# MCU_CTRL_MMR0_CFG0 register map
Vendor: Texas Instruments
Registers are 32-bit, read-write, reset 0x0 unless marked. A register's access mark holds for its fields unless they carry their own. Offsets are as the file gives them; [hi:lo] are bit positions; {n}, {i} and the like mark numbered series.

## MCU_CTRL_MMR0_CFG0 (part 3 of 3)
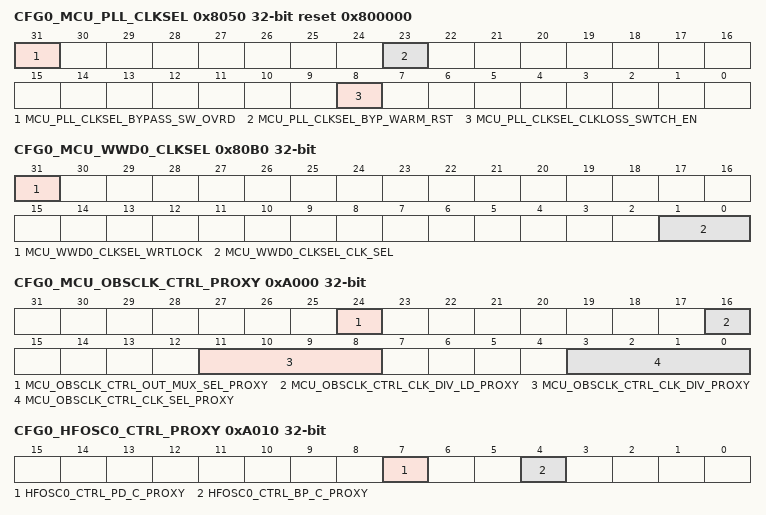
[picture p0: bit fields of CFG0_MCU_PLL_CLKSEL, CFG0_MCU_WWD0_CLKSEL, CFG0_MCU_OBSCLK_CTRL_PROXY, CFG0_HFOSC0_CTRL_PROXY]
0x8050 CFG0_MCU_PLL_CLKSEL reset 0x800000
  [31] MCU_PLL_CLKSEL_BYPASS_SW_OVRD — PLL Bypass warm reset software override When set, activates software control of exit from bypass mode on a mcu_reset_z for MCU_PLL0. This bit must not be set until after the corresponding byp_warm_rst bit has been cleared or the PLL will immediately enter bypass mode. Field values (others are reserved): 1'b0 - DEACTIVATE 1'b1 - ACTIVATE
  [23] MCU_PLL_CLKSEL_BYP_WARM_RST — PLL bypass mode after warm reset. This bit is only valid when bypass_sw_ovrd is set to 1'b1 to activate bypass software override. This bit is set (1'b1) when a MCU warm reset occurs and will keep MCU_PLL0 in bypass mode after reset exit until cleared by software. Field values (others are reserved): 1'b0 - EXIT_BYPASS 1'b1 - MAINTAIN_BYPASS
  [8] MCU_PLL_CLKSEL_CLKLOSS_SWTCH_EN — When set, activates automatic switching of MCU_PLL0 clock source to CLK_12M_RC if HFOSC0 clock loss is detected Field values (others are reserved): 1'b0 - DEACTIVATE 1'b1 - ACTIVATE
0x8058 CFG0_DEVICE_CLKOUT_32K_CTRL
  [1:0] DEVICE_CLKOUT_32K_CTRL_CLK_32K_RC_SEL — Selects the source of the device level 32KHz Clock Field values (others are reserved): 2'b00 - CLK_32K_RC 2'b01 - HFOSC0_CLKOUT_32K undefined - undefined 2'b11 - LFOSC0_CLKOUT
{0x8060+4i} CFG0_MCU_TIMER{i}_CLKSEL (i=0..3)
  [2:0] MCU_TIMER{i}_CLKSEL_CLK_SEL — Timer functional clock input select mux control (Reserved values default to HFOSC0_CLK) Field values (others are reserved): 3'b000 - HFOSC0_CLKOUT 3'b001 - MCU_SYSCLK0 / 2 3'b010 - CLK_12M_RC 3'b011 - MCU_PLL0_HSDIV5_CLKOUT 3'b100 - MCU_EXT_REFCLK0 3'b101 - DEVICE_CLKOUT_32K 3'b110 - CPSW0_CPTS_GENF0 3'b111 - CLK_32K_RC
0x8070 CFG0_MCU_GPIO_CLKSEL
  [1:0] MCU_GPIO_CLKSEL_CLK_SEL — MCU_GPIO clock selection. Must be set to MCU_SYSCLK0/4 whenever MCU_GPIO VBUS interface is activated. Other clock source may be selected as a clk_sel up clock for DeepSleep modes after MCU_GPIO is gated off through LPSC. Field values (others are reserved): 2'b00 - MCU_SYSCLK0_DIV4 2'b01 - LFSOSC_CLKOUT 2'b10 - CLK_32K 2'b11 - CLK_12M_RC
0x8080 CFG0_MCU_MCAN0_CLKSEL
  [1:0] MCU_MCAN0_CLKSEL_CLK_SEL — Selects the clock source for MCAN0 Field values (others are reserved): 2'b00 - MCU_PLL0_HSDIV4_CLKOUT 2'b01 - MCU_EXT_REFCLK0 2'b10 - HFOSC0_CLKOUT 2'b11 - HFOSC0_CLKOUT
0x8084 CFG0_MCU_MCAN1_CLKSEL
  [1:0] MCU_MCAN1_CLKSEL_CLK_SEL — Selects the clock source for MCAN1 Field values (others are reserved): 2'b00 - MCU_PLL0_HSDIV4_CLKOUT 2'b01 - MCU_EXT_REFCLK0 2'b10 - HFOSC0_CLKOUT 2'b11 - HFOSC0_CLKOUT
0x80A0 CFG0_MCU_SPI0_CLKSEL
  [16] MCU_SPI0_CLKSEL_MSTR_LB_CLKSEL — Controller mode receive capture clock loopback selection Field values (others are reserved): 1'b0 - INTERNAL_LOOPBACK 1'b1 - EXTERNAL_LOOPBACK
0x80A4 CFG0_MCU_SPI1_CLKSEL
  [16] MCU_SPI1_CLKSEL_MSTR_LB_CLKSEL — Controller mode receive capture clock loopback selection Field values (others are reserved): 1'b0 - INTERNAL_LOOPBACK 1'b1 - EXTERNAL_LOOPBACK
0x80B0 CFG0_MCU_WWD0_CLKSEL
  [31] MCU_WWD0_CLKSEL_WRTLOCK — When set, locks WWD0_CLKSEL from further writes until the next module reset. Field values (others are reserved): 1'b0 - UNLOCKED 1'b1 - LOCKED
  [1:0] MCU_WWD0_CLKSEL_CLK_SEL — Windowed watchdog timer functional clock input select mux control Field values (others are reserved): 2'b00 - HFOSC0_CLKOUT 2'b01 - DEVICE_CLKOUT_32K 2'b10 - CLK_12M_RC 2'b11 - CLK_32K_RC
0x9100 CFG0_CLAIMREG_P2_R0_READONLY ro
  [31:0] CLAIMREG_P2_R0_READONLY — Claim bits for Partition 2
0x9104 CFG0_CLAIMREG_P2_R1_READONLY ro
  [31:0] CLAIMREG_P2_R1_READONLY — Claim bits for Partition 2
0xA000 CFG0_MCU_OBSCLK_CTRL_PROXY
  [24] MCU_OBSCLK_CTRL_OUT_MUX_SEL_PROXY — MCU_OBSCLK pin output mux selection. Note, HFOSC0_CLK is a direct output from the HFOSC0, distinct from HFOSC0_CLKOUT. Note, when HFOSC0_CLK is selected (1'b1) the MCU_OBSCLK_CTRL_clk_sel field must be programmed to 4'b0001. Field values (others are reserved): 1'b0 - CLK_DIV_OUT 1'b1 - HFOSC0_CLK (clk_sel must be OFF)
  [16] MCU_OBSCLK_CTRL_CLK_DIV_LD_PROXY — Load the output divider value Writing 1 to this bit will generate a load pulse to load the OBSCLK divider value. This bit can be cleared but must not be set in the same write cycle in which the clk_div value is changed. Field values (others are reserved): 1'b0 - READY 1'b1 - LOAD
  [11:8] MCU_OBSCLK_CTRL_CLK_DIV_PROXY — MCU_OBSCLK pin clock selection output divider Output clock is divided by clk_div+1
  [3:0] MCU_OBSCLK_CTRL_CLK_SEL_PROXY — MCU_OBSCLK pin clock selection Field values (others are reserved): 4'b0000 - CLK_12M_RC 4'b0001 - OFF 4'b0010 - MCU_PLL0_HSDIV0_CLKOUT 4'b0011 - MCU_PLL0_HSDIV4_CLKOUT 4'b0100 - MCU_PLLCTRL_OBSCLK 4'b0101 - CLK_32K_RC 4'b0110 - HFOSC0_CLKOUT 4'b0111 - HFOSC0_CLKOUT_32K 4'b1000 - MCU_SYSCLK0 4'b1001 - DEVICE_CLKOUT_32K
0xA010 CFG0_HFOSC0_CTRL_PROXY
  [7] HFOSC0_CTRL_PD_C_PROXY — Oscillator powerdown control. Field values (others are reserved): 1'b0 - ACTIVE 1'b1 - POWERDOWN
  [4] HFOSC0_CTRL_BP_C_PROXY — Must Write '0'
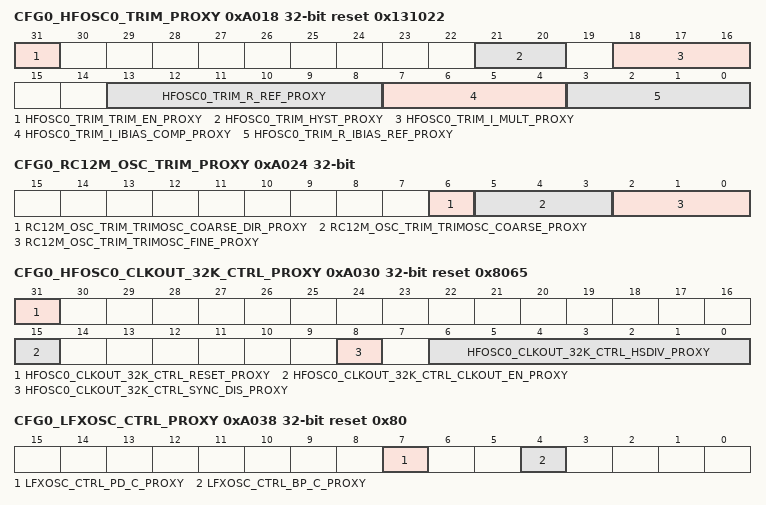
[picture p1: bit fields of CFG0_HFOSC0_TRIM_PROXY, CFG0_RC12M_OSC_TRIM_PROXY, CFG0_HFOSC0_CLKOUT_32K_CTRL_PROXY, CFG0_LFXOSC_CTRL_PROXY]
0xA018 CFG0_HFOSC0_TRIM_PROXY reset 0x131022
  [31] HFOSC0_TRIM_TRIM_EN_PROXY — Apply MMR values to OSC trim inputs instead of tie-offs Field values (others are reserved): 1'b0 - FIXED_TRIM 1'b1 - MMR_TRIM
  [21:20] HFOSC0_TRIM_HYST_PROXY — Sets comparator hysterisis Field values (others are reserved): 2'b00 - NO_HYS 2'b01 - TYPE1_HYS 2'b10 - TYPE2_HYS 2'b11 - BOTH_TYPES_HYS
  [18:16] HFOSC0_TRIM_I_MULT_PROXY — AGC AMP current multiplication gain Field values (others are reserved): 3'b000 - GAIN_0P250X 3'b001 - GAIN_0P375X 3'b010 - GAIN_0P500X 3'b011 - GAIN_0P625X 3'b100 - GAIN_0P750X 3'b101 - GAIN_0P875X 3'b110 - GAIN_1X 3'b111 - GAIN_1P250X
  [13:8] HFOSC0_TRIM_R_REF_PROXY — Sets the AMP AGC bias current Field values (others are reserved): 6'b000000 - R_REF_4X 6'b001000 - R_REF_6X 6'b010000 - R_REF_8X 6'b011000 - R_REF_10X 6'b100000 - R_REF_12X 6'b101000 - R_REF_14X 6'b110000 - R_REF_16X 6'b111000 - R_REF_18X
  [7:4] HFOSC0_TRIM_I_IBIAS_COMP_PROXY — Sets the COMP bias current Field values (others are reserved): 4'b0000 - I_BIAS_COMP_2P00X 4'b0001 - I_BIAS_COMP_2P25X 4'b0010 - I_BIAS_COMP_2P50X 4'b0011 - I_BIAS_COMP_2P75X 4'b0100 - I_BIAS_COMP__2P50X 4'b0101 - I_BIAS_COMP__2P75X 4'b0110 - I_BIAS_COMP_3P00X 4'b0111 - I_BIAS_COMP_3P25X 4'b1000 - I_BIAS_COMP__3P00X 4'b1001 - I_BIAS_COMP__3P25X 4'b1010 - I_BIAS_COMP_3P50X 4'b1011 - I_BIAS_COMP_3P75X 4'b1100 - I_BIAS_COMP_3P50X 4'b1101 - I_BIAS_COMP_3P75X 4'b1110 - I_BIAS_COMP_4P00X 4'b1111 - I_BIAS_COMP_4P25X
  [3:0] HFOSC0_TRIM_R_IBIAS_REF_PROXY — Sets the base IBIAS reference Field values (others are reserved): 4'b0000 - IBIAS_REF_1X 4'b0001 - IBIAS_REF_5X 4'b0010 - IBIAS_REF_3X (Default) 4'b0011 - IBIAS_REF_7X
0xA020 CFG0_HFOSC0_STAT_PROXY ro
  [0] HFOSC0_STAT_DS_ON_WFI_STAT_PROXY — Reflects the status of Device Manager Request to Disable HFOSC0 when it enters the WFI state (DeepSleep Entry) Field values (others are reserved): 1'b0 - NO_DEEPSLEEP_REQUEST 1'b1 - DEEPSLEEP_REQUEST
0xA024 CFG0_RC12M_OSC_TRIM_PROXY
  [6] RC12M_OSC_TRIM_TRIMOSC_COARSE_DIR_PROXY — Coarse adjustment direction. Field values (others are reserved): 1'b0 - TRIM_FREQ_LOWER 1'b1 - TRIM_FREQ_HIGHER
  [5:3] RC12M_OSC_TRIM_TRIMOSC_COARSE_PROXY — Coarse adjustment. Frequency is decreased or increased by 1.25 MHz per value based on the trimosc_coarse_dir value. Field values (others are reserved): 3'b000 - TRIM_0_MHZ 3'b001 - TRIM_1P25_MHZ 3'b010 - TRIM_2P50_MHZ 3'b011 - TRIM_3P75_MHZ 3'b100 - TRIM_4P00_MHZ 3'b101 - TRIM_5P25_MHZ 3'b110 - TRIM_6P50_MHZ 3'b111 - TRIM_7P75_MHZ
  [2:0] RC12M_OSC_TRIM_TRIMOSC_FINE_PROXY — Fine adjustment. Decreases the frequency by 250 KHz per value. Field values (others are reserved): 3'b000 - TRIM_0_KHZ 3'b001 - TRIM_250_KHZ 3'b010 - TRIM_500_KHZ 3'b011 - TRIM_750_KHZ 3'b100 - TRIM_1000_KHZ 3'b101 - TRIM_1250_KHZ 3'b110 - TRIM_1500_KHZ 3'b111 - TRIM_1750_KHZ
0xA030 CFG0_HFOSC0_CLKOUT_32K_CTRL_PROXY reset 0x8065
  [31] HFOSC0_CLKOUT_32K_CTRL_RESET_PROXY — Asynchronous Divider Reset. Field values (others are reserved): 1'b0 - ACTIVE 1'b1 - RESET
  [15] HFOSC0_CLKOUT_32K_CTRL_CLKOUT_EN_PROXY — HFOSC0_CLKOUT_32K output active Field values (others are reserved): 1'b0 - INACTIVE 1'b1 - ACTIVE
  [8] HFOSC0_CLKOUT_32K_CTRL_SYNC_DIS_PROXY — HFOSC0_CLKOUT_32K Synchronize Deactivate This bit must be written 0. Field values (others are reserved): 1'b0 - NORMAL
  [6:0] HFOSC0_CLKOUT_32K_CTRL_HSDIV_PROXY — HFOSC0_CLKOUT_32K divider: HFOSC0_CLKKOUT_32K Frequency = HFOSC0 Frequency / [8 * (hsdiv + 1)] Ex. HFOSC0 Frequency = 26MHz. hsdiv = 101 (Default) HFOSC0_CLKOUT_32K = 26MHz / (8 * (101+1)) = 26MHz / 816 = 31.9 KHz
0xA038 CFG0_LFXOSC_CTRL_PROXY reset 0x80
  [7] LFXOSC_CTRL_PD_C_PROXY — Oscillator powerdown control. When set, oscillator is deactivated. Oscillator output is tristated if bp_c=0 Field values (others are reserved): 1'b0 - ACTIVE 1'b1 - POWERDOWN
  [4] LFXOSC_CTRL_BP_C_PROXY — Oscillator bypass control. When set, oscillator is in bypass mode Field values (others are reserved): 1'b0 - ACTIVE 1'b1 - BYPASS
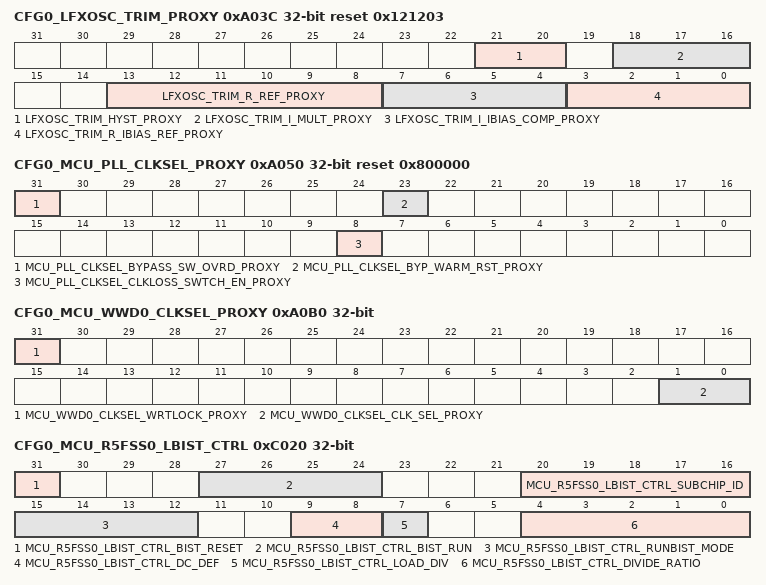
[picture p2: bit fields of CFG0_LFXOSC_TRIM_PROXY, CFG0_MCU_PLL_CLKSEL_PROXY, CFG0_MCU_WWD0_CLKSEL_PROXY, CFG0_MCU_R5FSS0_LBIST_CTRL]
0xA03C CFG0_LFXOSC_TRIM_PROXY reset 0x121203
  [21:20] LFXOSC_TRIM_HYST_PROXY — Sets comparator hysterisis Field values (others are reserved): 2'b00 - NO_HYS 2'b01 - TYPE1_HYS 2'b10 - TYPE2_HYS 2'b11 - BOTH_TYPES_HYS
  [18:16] LFXOSC_TRIM_I_MULT_PROXY — AGC AMP current multiplication gain Field values (others are reserved): 3'b000 - AMP_AGC_IBIAS_3X 3'b001 - AMP_AGC_IBIAS_4X 3'b010 - AMP_AGC_IBIAS_5X 3'b011 - AMP_AGC_IBIAS_6X 3'b100 - AMP_AGC_IBIAS_7X 3'b101 - AMP_AGC_IBIAS_8X 3'b110 - AMP_AGC_IBIAS_9X 3'b111 - AMP_AGC_IBIAS_10X
  [13:8] LFXOSC_TRIM_R_REF_PROXY — Sets the AMP AGC bias current Field values (others are reserved): 6'b000000 - OHMS_0K 6'b000001 - OHMS_24K 6'b000010 - OHMS_48K 6'b000011 - OHMS_73K 6'b000100 - OHMS_97K 6'b000101 - OHMS_121K 6'b000110 - OHMS_145K 6'b000111 - OHMS_169K 6'b001000 - OHMS_193K 6'b001001 - OHMS_218K 6'b001010 - OHMS_242K 6'b001011 - OHMS_266K 6'b001100 - OHMS_290K 6'b001101 - OHMS_314K 6'b001110 - OHMS_338K 6'b001111 - OHMS_363K 6'b010000 - OHMS_387K 6'b010001 - OHMS_411K 6'b010010 - OHMS_435K (Default) 6'b010011 - OHMS_459K 6'b010100 - OHMS_483K 6'b010101 - OHMS_508K 6'b010110 - OHMS_532K 6'b010111 - OHMS_556K 6'b011000 - OHMS_580K 6'b011001 - OHMS_604K 6'b011010 - OHMS_628K 6'b011011 - OHMS_653K 6'b011100 - OHMS_677K 6'b011101 - OHMS_701K 6'b011110 - OHMS_725K 6'b011111 - OHMS_749K 6'b100000 - OHMS_773K 6'b100001 - OHMS_798K 6'b100010 - OHMS_822K 6'b100011 - OHMS_846K 6'b100100 - OHMS_870K 6'b100101 - OHMS_894K 6'b100110 - OHMS_918K 6'b100111 - OHMS_943K 6'b101000 - OHMS_967K 6'b101001 - OHMS_991K 6'b101010 - OHMS_1015K 6'b101011 - OHMS_1039K 6'b101100 - OHMS_1063K 6'b101101 - OHMS_1088K 6'b101110 - OHMS_1112K 6'b101111 - OHMS_1136K 6'b110000 - OHMS_1160K 6'b110001 - OHMS_1184K 6'b110010 - OHMS_1208K 6'b110011 - OHMS_1233K 6'b110100 - OHMS_1257K 6'b110101 - OHMS_1281K 6'b110110 - OHMS_1305K 6'b110111 - OHMS_1329K 6'b111000 - OHMS_1353K 6'b111001 - OHMS_1378K 6'b111010 - OHMS_1402K 6'b111011 - OHMS_1426K 6'b111100 - OHMS_1450K 6'b111101 - OHMS_1474K 6'b111110 - OHMS_1498K 6'b111111 - OHMS_1523K
  [7:4] LFXOSC_TRIM_I_IBIAS_COMP_PROXY — Sets the COMP bias current Field values (others are reserved): 4'b0000 - BASE_IBIAS_REF_X2 4'b0001 - BASE_IBIAS_REF_X3 4'b0010 - BASE_IBIAS_REF_X4 4'b0011 - BASE_IBIAS_REF_X5 4'b0100 - BASE_IBIAS_REF_X6 4'b0101 - BASE_IBIAS_REF_X7 4'b0110 - BASE_IBIAS_REF_X8 4'b0111 - BASE_IBIAS_REF_X9 4'b1000 - BASE_IBIAS_REF_X10 4'b1001 - BASE_IBIAS_REF_X11 4'b1010 - BASE_IBIAS_REF_X12 4'b1011 - BASE_IBIAS_REF_X13 4'b1100 - BASE_IBIAS_REF_X14 4'b1101 - BASE_IBIAS_REF_X15 4'b1110 - BASE_IBIAS_REF_X16 4'b1111 - BASE_IBIAS_REF_X17
  [3:0] LFXOSC_TRIM_R_IBIAS_REF_PROXY — Sets the base IBIAS reference Field values (others are reserved): 4'b0000 - OHMS_512K 4'b0001 - OHMS_576K 4'b0010 - OHMS_640K 4'b0011 - OHMS_704K (Default) 4'b0100 - OHMS_768K 4'b0101 - OHMS_832K 4'b0110 - OHMS_896K 4'b0111 - OHMS_960K 4'b1000 - OHMS_1024K 4'b1001 - OHMS_1088K 4'b1010 - OHMS_1152K 4'b1011 - OHMS_1216K 4'b1100 - OHMS_1280K 4'b1101 - OHMS_1344K 4'b1110 - OHMS_1408K 4'b1111 - OHMS_1472K
0xA050 CFG0_MCU_PLL_CLKSEL_PROXY reset 0x800000
  [31] MCU_PLL_CLKSEL_BYPASS_SW_OVRD_PROXY — PLL Bypass warm reset software override When set, activates software control of exit from bypass mode on a mcu_reset_z for MCU_PLL0. This bit must not be set until after the corresponding byp_warm_rst bit has been cleared or the PLL will immediately enter bypass mode. Field values (others are reserved): 1'b0 - DEACTIVATE 1'b1 - ACTIVATE
  [23] MCU_PLL_CLKSEL_BYP_WARM_RST_PROXY — PLL bypass mode after warm reset. This bit is only valid when bypass_sw_ovrd is set to 1'b1 to activate bypass software override. This bit is set (1'b1) when a MCU warm reset occurs and will keep MCU_PLL0 in bypass mode after reset exit until cleared by software. Field values (others are reserved): 1'b0 - EXIT_BYPASS 1'b1 - MAINTAIN_BYPASS
  [8] MCU_PLL_CLKSEL_CLKLOSS_SWTCH_EN_PROXY — When set, activates automatic switching of MCU_PLL0 clock source to CLK_12M_RC if HFOSC0 clock loss is detected Field values (others are reserved): 1'b0 - DEACTIVATE 1'b1 - ACTIVATE
0xA058 CFG0_DEVICE_CLKOUT_32K_CTRL_PROXY
  [1:0] DEVICE_CLKOUT_32K_CTRL_CLK_32K_RC_SEL_PROXY — Selects the source of the device level 32KHz Clock Field values (others are reserved): 2'b00 - CLK_32K_RC 2'b01 - HFOSC0_CLKOUT_32K undefined - undefined 2'b11 - LFOSC0_CLKOUT
{0xA060+4i} CFG0_MCU_TIMER{i}_CLKSEL_PROXY (i=0..3)
  [2:0] MCU_TIMER{i}_CLKSEL_CLK_SEL_PROXY — Timer functional clock input select mux control (Reserved values default to HFOSC0_CLK) Field values (others are reserved): 3'b000 - HFOSC0_CLKOUT 3'b001 - MCU_SYSCLK0 / 2 3'b010 - CLK_12M_RC 3'b011 - MCU_PLL0_HSDIV5_CLKOUT 3'b100 - MCU_EXT_REFCLK0 3'b101 - DEVICE_CLKOUT_32K 3'b110 - CPSW0_CPTS_GENF0 3'b111 - CLK_32K_RC
0xA070 CFG0_MCU_GPIO_CLKSEL_PROXY
  [1:0] MCU_GPIO_CLKSEL_CLK_SEL_PROXY — MCU_GPIO clock selection. Must be set to MCU_SYSCLK0/4 whenever MCU_GPIO VBUS interface is activated. Other clock source may be selected as a clk_sel up clock for DeepSleep modes after MCU_GPIO is gated off through LPSC. Field values (others are reserved): 2'b00 - MCU_SYSCLK0_DIV4 2'b01 - LFSOSC_CLKOUT 2'b10 - CLK_32K 2'b11 - CLK_12M_RC
0xA080 CFG0_MCU_MCAN0_CLKSEL_PROXY
  [1:0] MCU_MCAN0_CLKSEL_CLK_SEL_PROXY — Selects the clock source for MCAN0 Field values (others are reserved): 2'b00 - MCU_PLL0_HSDIV4_CLKOUT 2'b01 - MCU_EXT_REFCLK0 2'b10 - HFOSC0_CLKOUT 2'b11 - HFOSC0_CLKOUT
0xA084 CFG0_MCU_MCAN1_CLKSEL_PROXY
  [1:0] MCU_MCAN1_CLKSEL_CLK_SEL_PROXY — Selects the clock source for MCAN1 Field values (others are reserved): 2'b00 - MCU_PLL0_HSDIV4_CLKOUT 2'b01 - MCU_EXT_REFCLK0 2'b10 - HFOSC0_CLKOUT 2'b11 - HFOSC0_CLKOUT
0xA0A0 CFG0_MCU_SPI0_CLKSEL_PROXY
  [16] MCU_SPI0_CLKSEL_MSTR_LB_CLKSEL_PROXY — Controller mode receive capture clock loopback selection Field values (others are reserved): 1'b0 - INTERNAL_LOOPBACK 1'b1 - EXTERNAL_LOOPBACK
0xA0A4 CFG0_MCU_SPI1_CLKSEL_PROXY
  [16] MCU_SPI1_CLKSEL_MSTR_LB_CLKSEL_PROXY — Controller mode receive capture clock loopback selection Field values (others are reserved): 1'b0 - INTERNAL_LOOPBACK 1'b1 - EXTERNAL_LOOPBACK
0xA0B0 CFG0_MCU_WWD0_CLKSEL_PROXY
  [31] MCU_WWD0_CLKSEL_WRTLOCK_PROXY — When set, locks WWD0_CLKSEL from further writes until the next module reset. Field values (others are reserved): 1'b0 - UNLOCKED 1'b1 - LOCKED
  [1:0] MCU_WWD0_CLKSEL_CLK_SEL_PROXY — Windowed watchdog timer functional clock input select mux control Field values (others are reserved): 2'b00 - HFOSC0_CLKOUT 2'b01 - DEVICE_CLKOUT_32K 2'b10 - CLK_12M_RC 2'b11 - CLK_32K_RC
0xB100 CFG0_CLAIMREG_P2_R0
  [31:0] CLAIMREG_P2_R0 — Claim bits for Partition 2
0xB104 CFG0_CLAIMREG_P2_R1
  [31:0] CLAIMREG_P2_R1 — Claim bits for Partition 2
0xC020 CFG0_MCU_R5FSS0_LBIST_CTRL
  [31] MCU_R5FSS0_LBIST_CTRL_BIST_RESET — This bitfield is not used.
  [27:24] MCU_R5FSS0_LBIST_CTRL_BIST_RUN — This bitfield is not used.
  [20:16] MCU_R5FSS0_LBIST_CTRL_SUBCHIP_ID — Specifies which sub-chip is to be tested
  [15:12] MCU_R5FSS0_LBIST_CTRL_RUNBIST_MODE — Runbist mode activate if all bits are 1
  [9:8] MCU_R5FSS0_LBIST_CTRL_DC_DEF — Clock delay after scan_activate switching
  [7] MCU_R5FSS0_LBIST_CTRL_LOAD_DIV — Loads LBIST clock divide ratio on transition from 0 to 1
  [4:0] MCU_R5FSS0_LBIST_CTRL_DIVIDE_RATIO — LBIST clock divide ratio
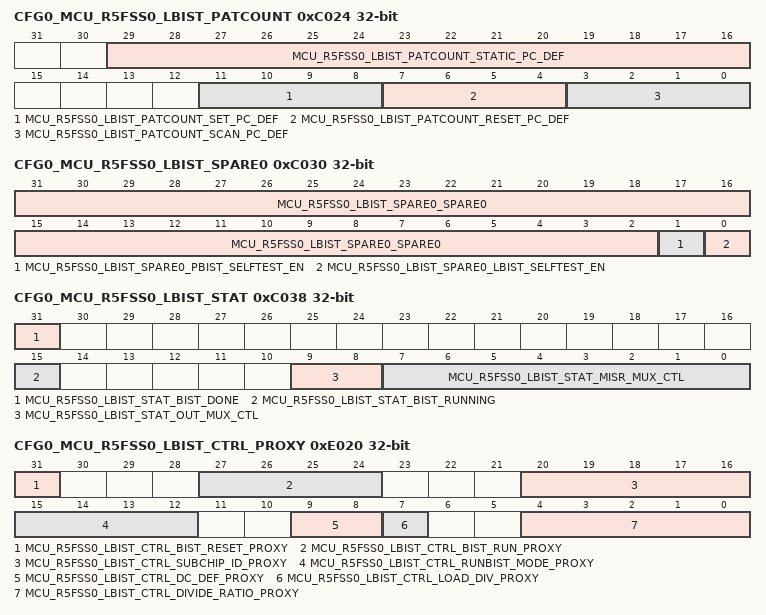
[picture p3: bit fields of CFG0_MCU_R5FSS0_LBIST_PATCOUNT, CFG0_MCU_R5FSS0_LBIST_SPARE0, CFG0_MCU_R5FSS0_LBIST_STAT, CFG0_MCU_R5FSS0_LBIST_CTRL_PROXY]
0xC024 CFG0_MCU_R5FSS0_LBIST_PATCOUNT
  [29:16] MCU_R5FSS0_LBIST_PATCOUNT_STATIC_PC_DEF — Number of stuck-at patterns to run
  [11:8] MCU_R5FSS0_LBIST_PATCOUNT_SET_PC_DEF — Number of set patterns to run
  [7:4] MCU_R5FSS0_LBIST_PATCOUNT_RESET_PC_DEF — Number of reset patterns to run
  [3:0] MCU_R5FSS0_LBIST_PATCOUNT_SCAN_PC_DEF — Number of chain test patterns to run
0xC028 CFG0_MCU_R5FSS0_LBIST_SEED0
  [31:0] MCU_R5FSS0_LBIST_SEED0_PRPG_DEF — Initial seed for PRPG (bits 31:0)
0xC02C CFG0_MCU_R5FSS0_LBIST_SEED1
  [20:0] MCU_R5FSS0_LBIST_SEED1_PRPG_DEF — Initial seed for PRPG (bits 52:32)
0xC030 CFG0_MCU_R5FSS0_LBIST_SPARE0
  [31:2] MCU_R5FSS0_LBIST_SPARE0_SPARE0 — LBIST spare bits
  [1] MCU_R5FSS0_LBIST_SPARE0_PBIST_SELFTEST_EN — Isolates MCU_R5FSS0 inputs/outputs related to Memory BIST (PBIST). Field values (others are reserved): 1'b0 - NOT_ISOLATED 1'b1 - ISOLATED
  [0] MCU_R5FSS0_LBIST_SPARE0_LBIST_SELFTEST_EN — Isolates MCU_R5FSS0 inputs/outputs related to Logic BIST (LBIST) Field values (others are reserved): 1'b0 - NOT_ISOLATED 1'b1 - ISOLATED
0xC034 CFG0_MCU_R5FSS0_LBIST_SPARE1
  [31:0] MCU_R5FSS0_LBIST_SPARE1_SPARE1 — LBIST spare bits
0xC038 CFG0_MCU_R5FSS0_LBIST_STAT access per field
  [31] MCU_R5FSS0_LBIST_STAT_BIST_DONE ro — LBIST is done
  [15] MCU_R5FSS0_LBIST_STAT_BIST_RUNNING ro — LBIST is running
  [9:8] MCU_R5FSS0_LBIST_STAT_OUT_MUX_CTL rw — Selects source of LBIST output 00 - LBIST IP PID value 01 - LBIST CTRL ID value 1x - MISR value
  [7:0] MCU_R5FSS0_LBIST_STAT_MISR_MUX_CTL rw — Selects block of 32 MISR bits to read. A value of 0 selects a compacted 32-bit version of the full MISR. A value of 1-32 select a 32-bit segment of the MISR.
0xC03C CFG0_MCU_R5FSS0_LBIST_MISR ro
  [31:0] MCU_R5FSS0_LBIST_MISR_MISR_RESULT — 32-bits of MISR value selected by misr_mux_ctl
0xD100 CFG0_CLAIMREG_P3_R0_READONLY ro
  [31:0] CLAIMREG_P3_R0_READONLY — Claim bits for Partition 3
0xE020 CFG0_MCU_R5FSS0_LBIST_CTRL_PROXY
  [31] MCU_R5FSS0_LBIST_CTRL_BIST_RESET_PROXY — This bitfield is not used.
  [27:24] MCU_R5FSS0_LBIST_CTRL_BIST_RUN_PROXY — This bitfield is not used.
  [20:16] MCU_R5FSS0_LBIST_CTRL_SUBCHIP_ID_PROXY — Specifies which sub-chip is to be tested
  [15:12] MCU_R5FSS0_LBIST_CTRL_RUNBIST_MODE_PROXY — Runbist mode activate if all bits are 1
  [9:8] MCU_R5FSS0_LBIST_CTRL_DC_DEF_PROXY — Clock delay after scan_activate switching
  [7] MCU_R5FSS0_LBIST_CTRL_LOAD_DIV_PROXY — Loads LBIST clock divide ratio on transition from 0 to 1
  [4:0] MCU_R5FSS0_LBIST_CTRL_DIVIDE_RATIO_PROXY — LBIST clock divide ratio
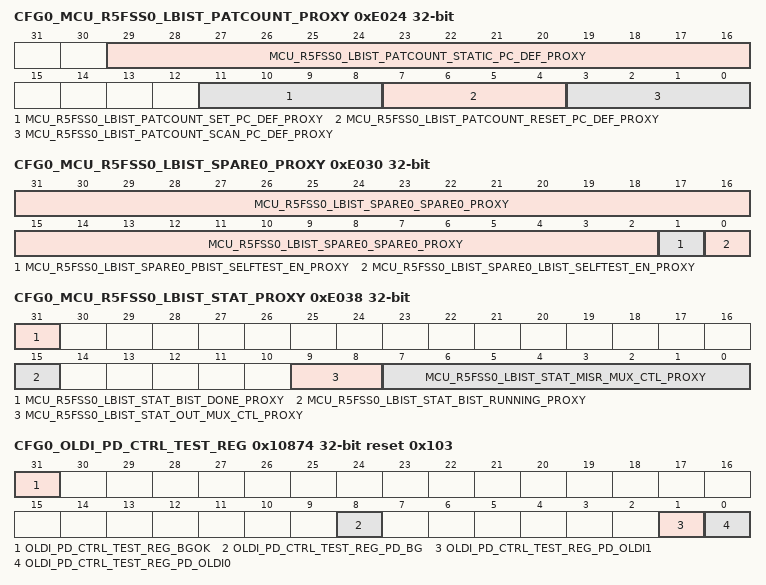
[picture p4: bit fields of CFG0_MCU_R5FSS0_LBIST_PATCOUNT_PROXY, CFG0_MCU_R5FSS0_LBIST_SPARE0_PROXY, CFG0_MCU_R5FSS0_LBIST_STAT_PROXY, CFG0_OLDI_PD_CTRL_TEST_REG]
0xE024 CFG0_MCU_R5FSS0_LBIST_PATCOUNT_PROXY
  [29:16] MCU_R5FSS0_LBIST_PATCOUNT_STATIC_PC_DEF_PROXY — Number of stuck-at patterns to run
  [11:8] MCU_R5FSS0_LBIST_PATCOUNT_SET_PC_DEF_PROXY — Number of set patterns to run
  [7:4] MCU_R5FSS0_LBIST_PATCOUNT_RESET_PC_DEF_PROXY — Number of reset patterns to run
  [3:0] MCU_R5FSS0_LBIST_PATCOUNT_SCAN_PC_DEF_PROXY — Number of chain test patterns to run
0xE028 CFG0_MCU_R5FSS0_LBIST_SEED0_PROXY
  [31:0] MCU_R5FSS0_LBIST_SEED0_PRPG_DEF_PROXY — Initial seed for PRPG (bits 31:0)
0xE02C CFG0_MCU_R5FSS0_LBIST_SEED1_PROXY
  [20:0] MCU_R5FSS0_LBIST_SEED1_PRPG_DEF_PROXY — Initial seed for PRPG (bits 52:32)
0xE030 CFG0_MCU_R5FSS0_LBIST_SPARE0_PROXY
  [31:2] MCU_R5FSS0_LBIST_SPARE0_SPARE0_PROXY — LBIST spare bits
  [1] MCU_R5FSS0_LBIST_SPARE0_PBIST_SELFTEST_EN_PROXY — Isolates MCU_R5FSS0 inputs/outputs related to Memory BIST (PBIST). Field values (others are reserved): 1'b0 - NOT_ISOLATED 1'b1 - ISOLATED
  [0] MCU_R5FSS0_LBIST_SPARE0_LBIST_SELFTEST_EN_PROXY — Isolates MCU_R5FSS0 inputs/outputs related to Logic BIST (LBIST) Field values (others are reserved): 1'b0 - NOT_ISOLATED 1'b1 - ISOLATED
0xE034 CFG0_MCU_R5FSS0_LBIST_SPARE1_PROXY
  [31:0] MCU_R5FSS0_LBIST_SPARE1_SPARE1_PROXY — LBIST spare bits
0xE038 CFG0_MCU_R5FSS0_LBIST_STAT_PROXY access per field
  [31] MCU_R5FSS0_LBIST_STAT_BIST_DONE_PROXY ro — LBIST is done
  [15] MCU_R5FSS0_LBIST_STAT_BIST_RUNNING_PROXY ro — LBIST is running
  [9:8] MCU_R5FSS0_LBIST_STAT_OUT_MUX_CTL_PROXY rw — Selects source of LBIST output 00 - LBIST IP PID value 01 - LBIST CTRL ID value 1x - MISR value
  [7:0] MCU_R5FSS0_LBIST_STAT_MISR_MUX_CTL_PROXY rw — Selects block of 32 MISR bits to read. A value of 0 selects a compacted 32-bit version of the full MISR. A value of 1-32 select a 32-bit segment of the MISR.
0xE03C CFG0_MCU_R5FSS0_LBIST_MISR_PROXY ro
  [31:0] MCU_R5FSS0_LBIST_MISR_MISR_RESULT_PROXY — 32-bits of MISR value selected by misr_mux_ctl
0xF100 CFG0_CLAIMREG_P3_R0
  [31:0] CLAIMREG_P3_R0 — Claim bits for Partition 3
0x10874 CFG0_OLDI_PD_CTRL_TEST_REG access per field reset 0x103
  [31] OLDI_PD_CTRL_TEST_REG_BGOK ro — Status of the Bandgap: 1 = Bandgap is On
  [8] OLDI_PD_CTRL_TEST_REG_PD_BG rw — When Set, forces the LVDS Bandgap into Power Down
  [1] OLDI_PD_CTRL_TEST_REG_PD_OLDI1 rw — When Set, overrides the biase_en of all OLDI1 LVDS IO to force power down
  [0] OLDI_PD_CTRL_TEST_REG_PD_OLDI0 rw — When Set, overrides the biase_en of all OLDI0 LVDS IO to force power down
{0x11100+4i} CFG0_CLAIMREG_P4_R{i}_READONLY ro (i=0..19)
  [31:0] CLAIMREG_P4_R{i}_READONLY — Claim bits for Partition 4
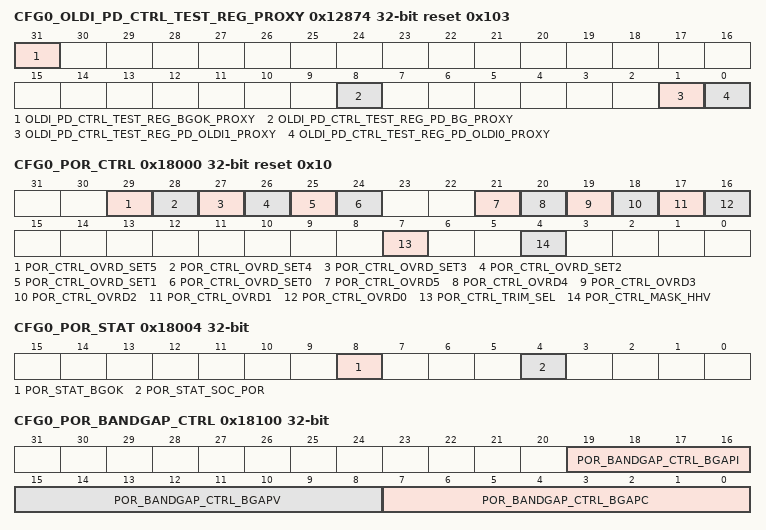
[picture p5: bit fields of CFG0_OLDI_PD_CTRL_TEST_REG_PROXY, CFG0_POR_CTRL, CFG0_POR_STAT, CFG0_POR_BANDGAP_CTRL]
0x12874 CFG0_OLDI_PD_CTRL_TEST_REG_PROXY access per field reset 0x103
  [31] OLDI_PD_CTRL_TEST_REG_BGOK_PROXY ro — Status of the Bandgap: 1 = Bandgap is On
  [8] OLDI_PD_CTRL_TEST_REG_PD_BG_PROXY rw — When Set, forces the LVDS Bandgap into Power Down
  [1] OLDI_PD_CTRL_TEST_REG_PD_OLDI1_PROXY rw — When Set, overrides the biase_en of all OLDI1 LVDS IO to force power down
  [0] OLDI_PD_CTRL_TEST_REG_PD_OLDI0_PROXY rw — When Set, overrides the biase_en of all OLDI0 LVDS IO to force power down
{0x13100+4i} CFG0_CLAIMREG_P4_R{i} (i=0..19)
  [31:0] CLAIMREG_P4_R{i} — Claim bits for Partition 4
0x18000 CFG0_POR_CTRL reset 0x10
  [29] POR_CTRL_OVRD_SET5 — Override value when override is active, for RESERVED output. Field values (others are reserved): 1'b0 - OVERRIDE_TO_0 1'b1 - OVERRIDE_TO_1
  [28] POR_CTRL_OVRD_SET4 — Override value when override is active, for POKLVB output. Field values (others are reserved): 1'b0 - OVERRIDE_TO_0 1'b1 - OVERRIDE_TO_1
  [27] POR_CTRL_OVRD_SET3 — Override value when override is active, for POKLVA output. Field values (others are reserved): 1'b0 - OVERRIDE_TO_0 1'b1 - OVERRIDE_TO_1
  [26] POR_CTRL_OVRD_SET2 — Override value when override is active, for POKHV output. Field values (others are reserved): 1'b0 - OVERRIDE_TO_0 1'b1 - OVERRIDE_TO_1
  [25] POR_CTRL_OVRD_SET1 — Override value when override is active, for BGOK output. Field values (others are reserved): 1'b0 - OVERRIDE_TO_0 1'b1 - OVERRIDE_TO_1
  [24] POR_CTRL_OVRD_SET0 — Override value when override is active, for PORHV output. Field values (others are reserved): 1'b0 - OVERRIDE_TO_0 1'b1 - OVERRIDE_TO_1
  [21] POR_CTRL_OVRD5 — Activates override of RESERVED output Field values (others are reserved): 1'b0 - NORMAL_OPERATION 1'b1 - OVERRIDE_OUTPUT
  [20] POR_CTRL_OVRD4 — Activates override of POKLVB output Field values (others are reserved): 1'b0 - NORMAL_OPERATION 1'b1 - OVERRIDE_OUTPUT
  [19] POR_CTRL_OVRD3 — Activates override of POKLVA output Field values (others are reserved): 1'b0 - NORMAL_OPERATION 1'b1 - OVERRIDE_OUTPUT
  [18] POR_CTRL_OVRD2 — Activates override of POKHV output Field values (others are reserved): 1'b0 - NORMAL_OPERATION 1'b1 - OVERRIDE_OUTPUT
  [17] POR_CTRL_OVRD1 — Activates override of BGOK output Field values (others are reserved): 1'b0 - NORMAL_OPERATION 1'b1 - OVERRIDE_OUTPUT
  [16] POR_CTRL_OVRD0 — Activates override of PORHV output Field values (others are reserved): 1'b0 - NORMAL_OPERATION 1'b1 - OVERRIDE_OUTPUT
  [7] POR_CTRL_TRIM_SEL — POR Trim Select - Fixed value or from POR_BANDGAP_CTRL and POR_POKxxx_CTRL registers MMRs Field values (others are reserved): 1'b0 - FIXED_TRIM 1'b1 - MMR_TRIM
  [4] POR_CTRL_MASK_HHV — Mask HHV/SOC_PORz outputs when applying new trim values Field values (others are reserved): 1'b0 - UNMASK 1'b1 - MASK
0x18004 CFG0_POR_STAT ro
  [8] POR_STAT_BGOK — Bandgap OK status Field values (others are reserved): 1'b0 - UNKNOWN 1'b1 - OK
  [4] POR_STAT_SOC_POR — POR module status Field values (others are reserved): 1'b0 - POR_IS_ACTIVE 1'b1 - POR_IS_RESET
0x18100 CFG0_POR_BANDGAP_CTRL
  [19:16] POR_BANDGAP_CTRL_BGAPI — Bandgap output current trim bits
  [15:8] POR_BANDGAP_CTRL_BGAPV — Bandgap output voltage magnitude trim bits
  [7:0] POR_BANDGAP_CTRL_BGAPC — Bandgap slope trim bits.
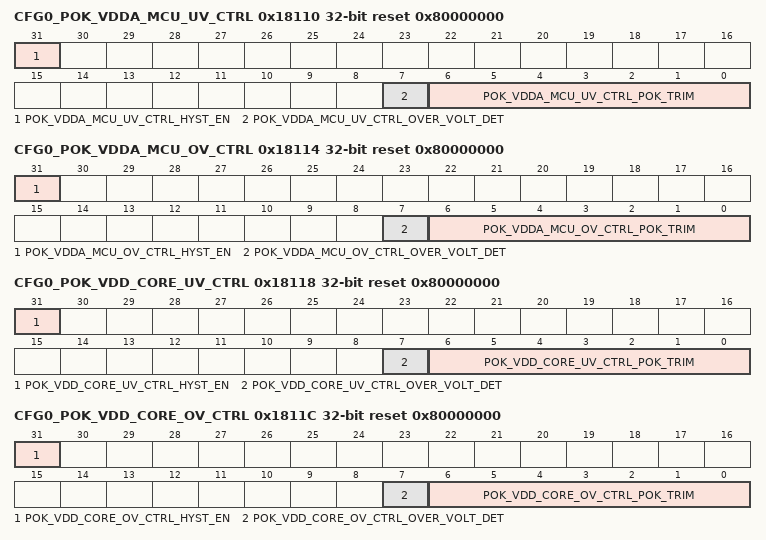
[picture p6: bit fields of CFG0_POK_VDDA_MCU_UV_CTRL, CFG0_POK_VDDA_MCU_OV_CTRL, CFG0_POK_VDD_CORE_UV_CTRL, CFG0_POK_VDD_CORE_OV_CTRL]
0x18110 CFG0_POK_VDDA_MCU_UV_CTRL reset 0x80000000
  [31] POK_VDDA_MCU_UV_CTRL_HYST_EN — Activate POK hysteresis Field values (others are reserved): 1'b0 - INACTIVE 1'b1 - ACTIVE
  [7] POK_VDDA_MCU_UV_CTRL_OVER_VOLT_DET — Over / under voltage detection mode Field values (others are reserved): 1'b0 - UNDERVOLTAGE_MODE 1'b1 - OVERVOLTAGE_MODE
  [6:0] POK_VDDA_MCU_UV_CTRL_POK_TRIM — POK Trim Value from Fuse
0x18114 CFG0_POK_VDDA_MCU_OV_CTRL reset 0x80000000
  [31] POK_VDDA_MCU_OV_CTRL_HYST_EN — Activate POK hysteresis Field values (others are reserved): 1'b0 - INACTIVE 1'b1 - ACTIVE
  [7] POK_VDDA_MCU_OV_CTRL_OVER_VOLT_DET — Over / under voltage detection mode Field values (others are reserved): 1'b0 - UNDERVOLTAGE_MODE 1'b1 - OVERVOLTAGE_MODE
  [6:0] POK_VDDA_MCU_OV_CTRL_POK_TRIM — POK Trim Value from Fuse
0x18118 CFG0_POK_VDD_CORE_UV_CTRL reset 0x80000000
  [31] POK_VDD_CORE_UV_CTRL_HYST_EN — Activate POK hysteresis Field values (others are reserved): 1'b0 - INACTIVE 1'b1 - ACTIVE
  [7] POK_VDD_CORE_UV_CTRL_OVER_VOLT_DET — Over / under voltage detection mode Field values (others are reserved): 1'b0 - UNDERVOLTAGE_MODE 1'b1 - OVERVOLTAGE_MODE
  [6:0] POK_VDD_CORE_UV_CTRL_POK_TRIM — POK Trim Value from Fuse
0x1811C CFG0_POK_VDD_CORE_OV_CTRL reset 0x80000000
  [31] POK_VDD_CORE_OV_CTRL_HYST_EN — Activate POK hysteresis Field values (others are reserved): 1'b0 - INACTIVE 1'b1 - ACTIVE
  [7] POK_VDD_CORE_OV_CTRL_OVER_VOLT_DET — Over / under voltage detection mode Field values (others are reserved): 1'b0 - UNDERVOLTAGE_MODE 1'b1 - OVERVOLTAGE_MODE
  [6:0] POK_VDD_CORE_OV_CTRL_POK_TRIM — POK Trim Value from Fuse
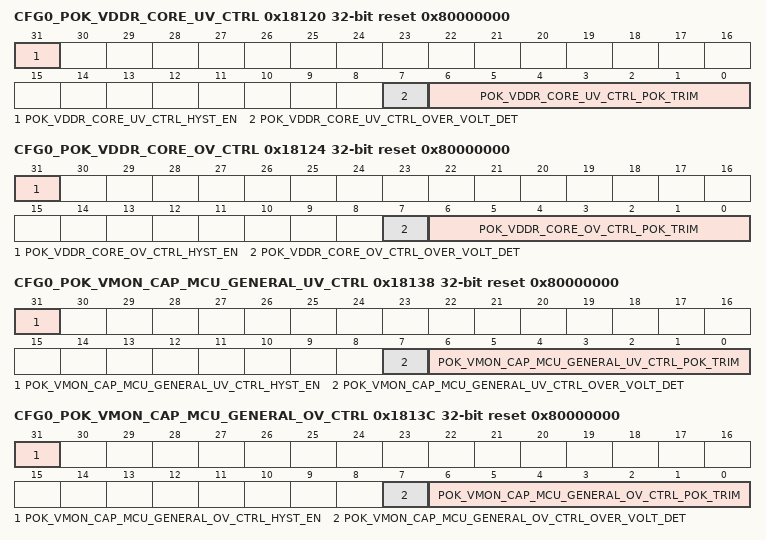
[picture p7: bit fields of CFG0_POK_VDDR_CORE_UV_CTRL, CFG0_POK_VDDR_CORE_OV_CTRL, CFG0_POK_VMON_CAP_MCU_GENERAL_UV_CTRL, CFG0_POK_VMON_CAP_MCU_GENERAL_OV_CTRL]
0x18120 CFG0_POK_VDDR_CORE_UV_CTRL reset 0x80000000
  [31] POK_VDDR_CORE_UV_CTRL_HYST_EN — Activate POK hysteresis Field values (others are reserved): 1'b0 - INACTIVE 1'b1 - ACTIVE
  [7] POK_VDDR_CORE_UV_CTRL_OVER_VOLT_DET — Over / under voltage detection mode Field values (others are reserved): 1'b0 - UNDERVOLTAGE_MODE 1'b1 - OVERVOLTAGE_MODE
  [6:0] POK_VDDR_CORE_UV_CTRL_POK_TRIM — POK Trim Value from Fuse
0x18124 CFG0_POK_VDDR_CORE_OV_CTRL reset 0x80000000
  [31] POK_VDDR_CORE_OV_CTRL_HYST_EN — Activate POK hysteresis Field values (others are reserved): 1'b0 - INACTIVE 1'b1 - ACTIVE
  [7] POK_VDDR_CORE_OV_CTRL_OVER_VOLT_DET — Over / under voltage detection mode Field values (others are reserved): 1'b0 - UNDERVOLTAGE_MODE 1'b1 - OVERVOLTAGE_MODE
  [6:0] POK_VDDR_CORE_OV_CTRL_POK_TRIM — POK Trim Value from Fuse
0x18138 CFG0_POK_VMON_CAP_MCU_GENERAL_UV_CTRL reset 0x80000000
  [31] POK_VMON_CAP_MCU_GENERAL_UV_CTRL_HYST_EN — Activate POK hysteresis Field values (others are reserved): 1'b0 - INACTIVE 1'b1 - ACTIVE
  [7] POK_VMON_CAP_MCU_GENERAL_UV_CTRL_OVER_VOLT_DET — Over / under voltage detection mode Field values (others are reserved): 1'b0 - UNDERVOLTAGE_MODE 1'b1 - OVERVOLTAGE_MODE
  [6:0] POK_VMON_CAP_MCU_GENERAL_UV_CTRL_POK_TRIM — POK Trim Value from Fuse
0x1813C CFG0_POK_VMON_CAP_MCU_GENERAL_OV_CTRL reset 0x80000000
  [31] POK_VMON_CAP_MCU_GENERAL_OV_CTRL_HYST_EN — Activate POK hysteresis Field values (others are reserved): 1'b0 - INACTIVE 1'b1 - ACTIVE
  [7] POK_VMON_CAP_MCU_GENERAL_OV_CTRL_OVER_VOLT_DET — Over / under voltage detection mode Field values (others are reserved): 1'b0 - UNDERVOLTAGE_MODE 1'b1 - OVERVOLTAGE_MODE
  [6:0] POK_VMON_CAP_MCU_GENERAL_OV_CTRL_POK_TRIM — POK Trim Value from Fuse
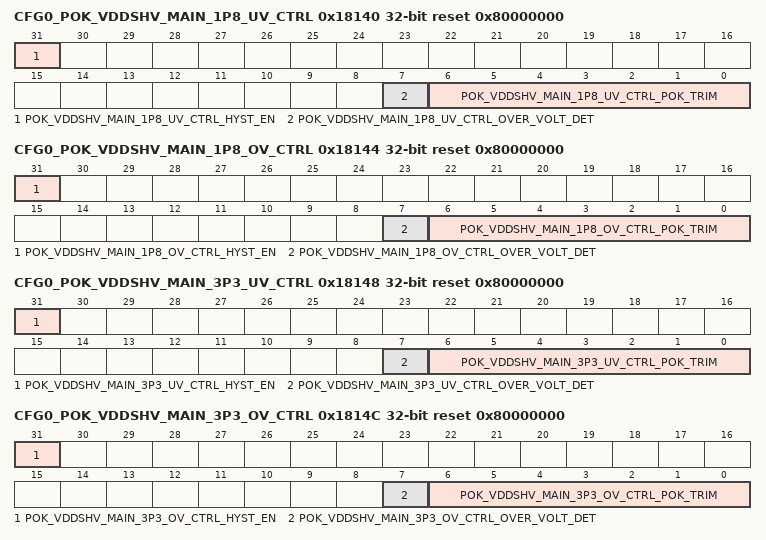
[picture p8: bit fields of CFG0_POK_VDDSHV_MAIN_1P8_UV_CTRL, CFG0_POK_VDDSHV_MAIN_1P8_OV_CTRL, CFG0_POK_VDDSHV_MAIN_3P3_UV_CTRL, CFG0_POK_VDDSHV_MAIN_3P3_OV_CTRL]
0x18140 CFG0_POK_VDDSHV_MAIN_1P8_UV_CTRL reset 0x80000000
  [31] POK_VDDSHV_MAIN_1P8_UV_CTRL_HYST_EN — Activate POK hysteresis Field values (others are reserved): 1'b0 - INACTIVE 1'b1 - ACTIVE
  [7] POK_VDDSHV_MAIN_1P8_UV_CTRL_OVER_VOLT_DET — Over / under voltage detection mode Field values (others are reserved): 1'b0 - UNDERVOLTAGE_MODE 1'b1 - OVERVOLTAGE_MODE
  [6:0] POK_VDDSHV_MAIN_1P8_UV_CTRL_POK_TRIM — POK Trim Value from Fuse
0x18144 CFG0_POK_VDDSHV_MAIN_1P8_OV_CTRL reset 0x80000000
  [31] POK_VDDSHV_MAIN_1P8_OV_CTRL_HYST_EN — Activate POK hysteresis Field values (others are reserved): 1'b0 - INACTIVE 1'b1 - ACTIVE
  [7] POK_VDDSHV_MAIN_1P8_OV_CTRL_OVER_VOLT_DET — Over / under voltage detection mode Field values (others are reserved): 1'b0 - UNDERVOLTAGE_MODE 1'b1 - OVERVOLTAGE_MODE
  [6:0] POK_VDDSHV_MAIN_1P8_OV_CTRL_POK_TRIM — POK Trim Value from Fuse
0x18148 CFG0_POK_VDDSHV_MAIN_3P3_UV_CTRL reset 0x80000000
  [31] POK_VDDSHV_MAIN_3P3_UV_CTRL_HYST_EN — Activate POK hysteresis Field values (others are reserved): 1'b0 - INACTIVE 1'b1 - ACTIVE
  [7] POK_VDDSHV_MAIN_3P3_UV_CTRL_OVER_VOLT_DET — Over / under voltage detection mode Field values (others are reserved): 1'b0 - UNDERVOLTAGE_MODE 1'b1 - OVERVOLTAGE_MODE
  [6:0] POK_VDDSHV_MAIN_3P3_UV_CTRL_POK_TRIM — POK Trim Value from Fuse
0x1814C CFG0_POK_VDDSHV_MAIN_3P3_OV_CTRL reset 0x80000000
  [31] POK_VDDSHV_MAIN_3P3_OV_CTRL_HYST_EN — Activate POK hysteresis Field values (others are reserved): 1'b0 - INACTIVE 1'b1 - ACTIVE
  [7] POK_VDDSHV_MAIN_3P3_OV_CTRL_OVER_VOLT_DET — Over / under voltage detection mode Field values (others are reserved): 1'b0 - UNDERVOLTAGE_MODE 1'b1 - OVERVOLTAGE_MODE
  [6:0] POK_VDDSHV_MAIN_3P3_OV_CTRL_POK_TRIM — POK Trim Value from Fuse
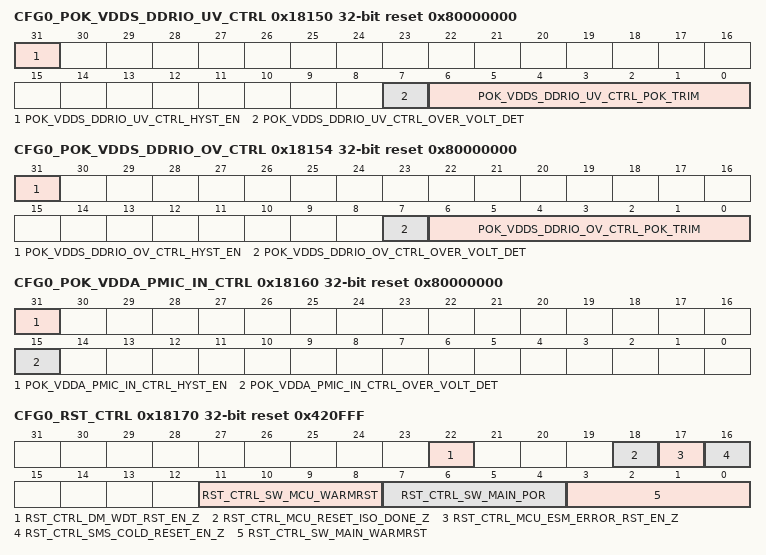
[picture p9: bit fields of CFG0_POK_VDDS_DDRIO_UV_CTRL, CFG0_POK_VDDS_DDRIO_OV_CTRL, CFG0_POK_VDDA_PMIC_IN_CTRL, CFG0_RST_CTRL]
0x18150 CFG0_POK_VDDS_DDRIO_UV_CTRL reset 0x80000000
  [31] POK_VDDS_DDRIO_UV_CTRL_HYST_EN — Activate POK hysteresis Field values (others are reserved): 1'b0 - INACTIVE 1'b1 - ACTIVE
  [7] POK_VDDS_DDRIO_UV_CTRL_OVER_VOLT_DET — Over / under voltage detection mode Field values (others are reserved): 1'b0 - UNDERVOLTAGE_MODE 1'b1 - OVERVOLTAGE_MODE
  [6:0] POK_VDDS_DDRIO_UV_CTRL_POK_TRIM — POK Trim Value from Fuse
0x18154 CFG0_POK_VDDS_DDRIO_OV_CTRL reset 0x80000000
  [31] POK_VDDS_DDRIO_OV_CTRL_HYST_EN — Activate POK hysteresis Field values (others are reserved): 1'b0 - INACTIVE 1'b1 - ACTIVE
  [7] POK_VDDS_DDRIO_OV_CTRL_OVER_VOLT_DET — Over / under voltage detection mode Field values (others are reserved): 1'b0 - UNDERVOLTAGE_MODE 1'b1 - OVERVOLTAGE_MODE
  [6:0] POK_VDDS_DDRIO_OV_CTRL_POK_TRIM — POK Trim Value from Fuse
0x18160 CFG0_POK_VDDA_PMIC_IN_CTRL reset 0x80000000
  [31] POK_VDDA_PMIC_IN_CTRL_HYST_EN — Activate POK hysteresis Field values (others are reserved): 1'b0 - INACTIVE 1'b1 - ACTIVE
  [15] POK_VDDA_PMIC_IN_CTRL_OVER_VOLT_DET — Over / under voltage detection mode Field values (others are reserved): 1'b0 - UNDERVOLTAGE_MODE 1'b1 - OVERVOLTAGE_MODE
0x18170 CFG0_RST_CTRL reset 0x420FFF
  [22] RST_CTRL_DM_WDT_RST_EN_Z — Block Reset from DM WDT propogating to MCU domain Field values (others are reserved): 1'b0 - PROPOGATE 1'b1 - BLOCK
  [18] RST_CTRL_MCU_RESET_ISO_DONE_Z — Block Main Domain Warm Reset MCU domain Field values (others are reserved): 1'b0 - PROPOGATE 1'b1 - BLOCK
  [17] RST_CTRL_MCU_ESM_ERROR_RST_EN_Z — Block Reset of MCU by ESM Field values (others are reserved): 1'b0 - PROPOGATE 1'b1 - BLOCK
  [16] RST_CTRL_SMS_COLD_RESET_EN_Z — Block Reset of MCU by SMS Field values (others are reserved): 1'b0 - PROPOGATE 1'b1 - BLOCK
  [11:8] RST_CTRL_SW_MCU_WARMRST — Causes MAIN Domain Warm Reset. This is a fault tolerant bitfield. Automatically resets to 4'b1111 after write. Field values (others are reserved): 4'b0110 - FORCE_RESET 4'b1111 - INACTIVE
  [7:4] RST_CTRL_SW_MAIN_POR — Causes MAIN Domain Power On Reset. This is a fault tolerant bitfield. Automatically resets to 4'b1111 after write. Field values (others are reserved): 4'b0110 - FORCE_RESET 4'b1111 - INACTIVE
  [3:0] RST_CTRL_SW_MAIN_WARMRST — Causes MAIN Domain Warm Reset. This is a fault tolerant bitfield. Automatically resets to 4'b1111 after write. Field values (others are reserved): 4'b0110 - FORCE_RESET 4'b1111 - INACTIVE
0x18174 CFG0_RST_STAT ro
  [0] RST_STAT_MAIN_RESETSTATZ — Status of Main Domain Reset: Field values (others are reserved): 1'b0 - BLOCKED 1'b1 - PROPOGATE
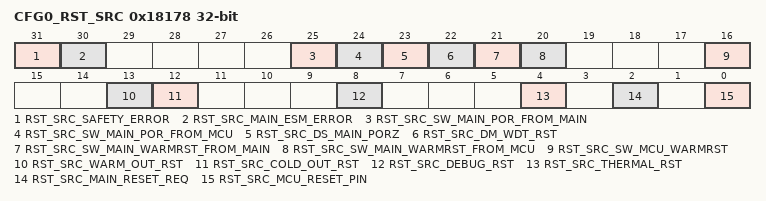
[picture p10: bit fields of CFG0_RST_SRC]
0x18178 CFG0_RST_SRC access not given
  [31] RST_SRC_SAFETY_ERROR — Reset Caused by MCU ESM Error. Write 1 to Clear. Field values (others are reserved): 1'b0 - UNKNOWN 1'b1 - DETECTED (access R/W1TC)
  [30] RST_SRC_MAIN_ESM_ERROR — Reset Caused by Main ESM Error. Write 1 to Clear. Field values (others are reserved): 1'b0 - UNKNOWN 1'b1 - DETECTED (access R/W1TC)
  [25] RST_SRC_SW_MAIN_POR_FROM_MAIN — Software Main Power On Reset From CTRL_MMR0. Write 1 to Clear. Field values (others are reserved): 1'b0 - UNKNOWN 1'b1 - DETECTED (access R/W1TC)
  [24] RST_SRC_SW_MAIN_POR_FROM_MCU — Software Main Power On Reset From MCU_CTRL_MMR0. Write 1 to Clear. Field values (others are reserved): 1'b0 - UNKNOWN 1'b1 - DETECTED (access R/W1TC)
  [23] RST_SRC_DS_MAIN_PORZ — Reset of Main/Wkup Domains while in Deep Sleep, as a result of an MCU Warm Reset. Write 1 to Clear. Field values (others are reserved): 1'b0 - UNKNOWN 1'b1 - DETECTED (access R/W1TC)
  [22] RST_SRC_DM_WDT_RST — Watchdog Initiated Reset. Write 1 to Clear. Field values (others are reserved): 1'b0 - UNKNOWN 1'b1 - DETECTED (access R/W1TC)
  [21] RST_SRC_SW_MAIN_WARMRST_FROM_MAIN — Software Main Warm Reset From CTRL_MMR0. Write 1 to Clear. Field values (others are reserved): 1'b0 - UNKNOWN 1'b1 - DETECTED (access R/W1TC)
  [20] RST_SRC_SW_MAIN_WARMRST_FROM_MCU — Software Main Warm Reset From MCU_CTRL_MMR0. Write 1 to Clear. Field values (others are reserved): 1'b0 - UNKNOWN 1'b1 - DETECTED (access R/W1TC)
  [16] RST_SRC_SW_MCU_WARMRST — Software Warm Reset. Write 1 to Clear. Field values (others are reserved): 1'b0 - UNKNOWN 1'b1 - DETECTED (access R/W1TC)
  [13] RST_SRC_WARM_OUT_RST — SMS Warm Reset. Write 1 to Clear. Field values (others are reserved): 1'b0 - UNKNOWN 1'b1 - DETECTED (access R/W1TC)
  [12] RST_SRC_COLD_OUT_RST — SMS Cold Reset. Write 1 to Clear. Field values (others are reserved): 1'b0 - UNKNOWN 1'b1 - DETECTED (access R/W1TC)
  [8] RST_SRC_DEBUG_RST — Debug Subsystem Initiated Reset. Write 1 to Clear. Field values (others are reserved): 1'b0 - UNKNOWN 1'b1 - DETECTED (access R/W1TC)
  [4] RST_SRC_THERMAL_RST — Thermal Reset. Write 1 to Clear. Field values (others are reserved): 1'b0 - UNKNOWN 1'b1 - DETECTED (access R/W1TC)
  [2] RST_SRC_MAIN_RESET_REQ — Main Reset Pin. Write 1 to Clear. Field values (others are reserved): 1'b0 - UNKNOWN 1'b1 - DETECTED (access R/W1TC)
  [0] RST_SRC_MCU_RESET_PIN — Rest Caused by MCU Reset Pin. Write 1 to Clear. Field values (others are reserved): 1'b0 - UNKNOWN 1'b1 - DETECTED (access R/W1TC)
